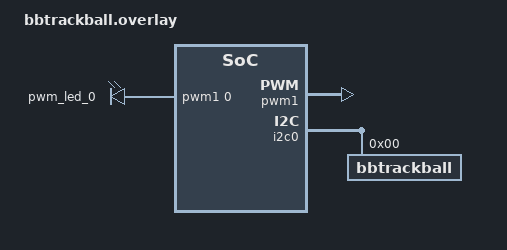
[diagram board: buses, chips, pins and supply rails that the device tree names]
/*
*
* Copyright (c) 2025 ZitaoTech
* SPDX-License-Identifier: MIT
*
*/
#include <zephyr/dt-bindings/input/input-event-codes.h>

/ {
    chosen {
        zmk,trackball_led = &trackball_led;
    };
    trackball_led: pwmledo{
        compatible = "pwm-leds";
        pwm_led_0 {
            pwms = <&pwm1 0 PWM_USEC(20) PWM_POLARITY_NORMAL>;
        };
    };

};

&pwm1 {
    status = "okay";
    pinctrl-0 = <&pwm1_default>;
    pinctrl-1 = <&pwm1_sleep>;
    pinctrl-names = "default", "sleep";
};

&i2c0 {
    bbtrackball: bbtrackball@0 {
        compatible = "zmk,bbtrackball";
        reg = <0x0>;
        status = "okay";
    };
};

/ {
    split_inputs {
        #address-cells = <1>;
        #size-cells = <0>;

        /* BB Trackball */
        bbtrackball_split: bbtrackball_split@0 {
            compatible = "zmk,input-split";
            reg = <0>;
        };

    };

    /* Listeners */
    bbtrackball_listener: bbtrackball_listener {
        compatible = "zmk,input-listener";
        status = "disabled";
        device = <&bbtrackball_split>;
    };

};


&bbtrackball_split {
    device = <&bbtrackball>;
};

/* 引脚定义在板目录 config/boards/arm/sofle_dongle/（属于板子，不属于模块）：
 * 引脚号在 Kconfig.defconfig 的按半段里，pinctrl 的 psels 在 lf.dtsi / rt.dtsi */

